# K1921VK028 register map
Vendor: NIIET; Series: K1921VKx; File version: 2.17
CPU: CM4 r0p1, little endian, MPU, FPU, 4 interrupt priority bits
Registers are 32-bit, read-write, reset 0x0 unless marked. A register's access mark holds for its fields unless they carry their own. Offsets are from the block's base; [hi:lo] are bit positions; lines under a group give offsets from that group; {n}, {i} and the like mark numbered series; 'fields as' and 'values as' point back to an identical list.

## RCU — Reset and clock unit registers
Base 0x40081000
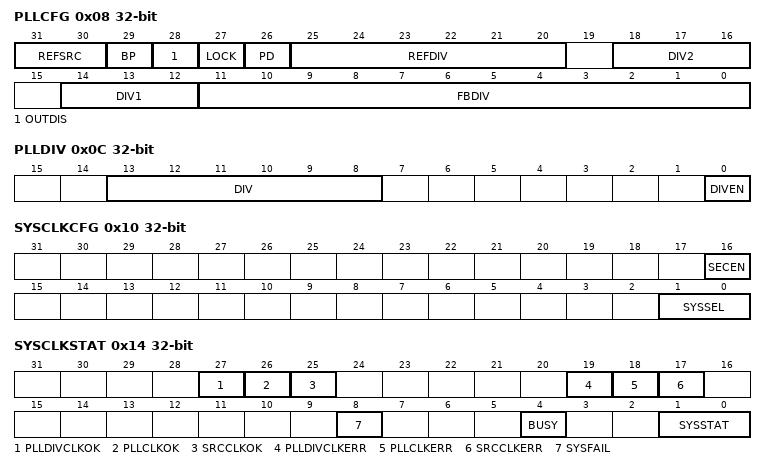
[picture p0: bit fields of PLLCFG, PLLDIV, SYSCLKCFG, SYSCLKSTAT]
0x08 PLLCFG — PLL Configuration Register
  [31:30] REFSRC — Reference clock source
    0=OSECLK (external oscillator); 1=OSICLK (internal oscillator); 2=PLLEXTCLK (external PLL clock source)
  [29] BP — Bypass PLL reference clock
  [28] OUTDIS — Disable PLL output clock
  [27] LOCK ro — Lock status of stable PLL output clock
  [26] PD — PLL PowerDown enable bit
  [25:20] REFDIV — PLL reference clock divider
  [18:16] DIV2 — Output DIV2 coefficient
  [14:12] DIV1 — Output DIV1 coefficient
  [11:0] FBDIV — PLL FBDIV Coefficient
0x0C PLLDIV — PLL Divider Register
  [13:8] DIV — PLL divider coefficent
  [0] DIVEN — PLL Divider enable bit
0x10 SYSCLKCFG — System Clock Configuration Register
  [16] SECEN — Enable clock security system
  [1:0] SYSSEL — System clock source selection
    0=REFCLK (reference clock); 1=SRCCLK (additional clock source); 2=PLLCLK (PLL output clock); 3=PLLDIVCLK (PLL divided clock)
0x14 SYSCLKSTAT ro — System Clock Status Register
  [27] PLLDIVCLKOK — PLL divided clock good
  [26] PLLCLKOK — PLL clock good
  [25] SRCCLKOK — Additional clock source good
  [19] PLLDIVCLKERR — PLL divided clock fail
  [18] PLLCLKERR — PLL clock fail
  [17] SRCCLKERR — Additional clock source fail
  [8] SYSFAIL — Error in current clock was detected
  [4] BUSY — Clock manager is busy, for example, when change clock source
  [1:0] SYSSTAT — Current system clock source
    on read: 0=REFCLK (reference clock); 1=SRCCLK (additional clock source); 2=PLLCLK (PLL output clock); 3=PLLDIVCLK (PLL divided clock)
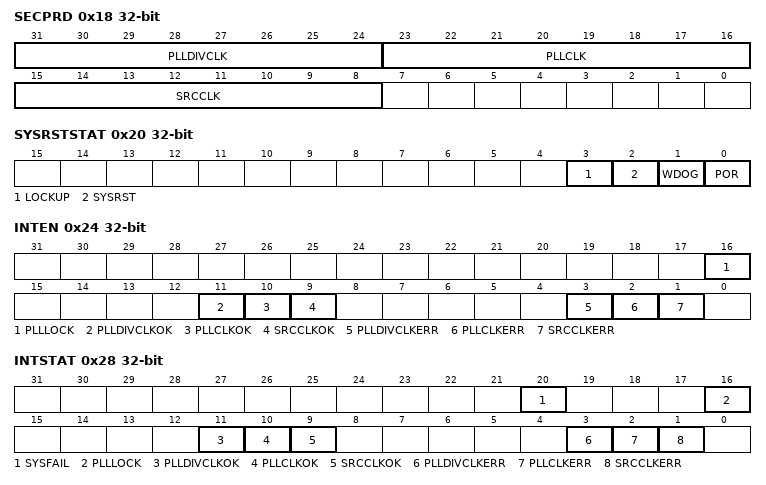
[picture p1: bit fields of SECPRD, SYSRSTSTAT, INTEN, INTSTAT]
0x18 SECPRD — Security Sysytem Clock Period Register 0
  [31:24] PLLDIVCLK — Clock source 3 max counter value for clock fail detection
  [23:16] PLLCLK — Clock source 2 max counter value for clock fail detection
  [15:8] SRCCLK — Additional clock source max counter value for fail detection
0x1C SYSRSTCFG — System Reset Configuration Register
  [0] LOCKUPEN — Enable reset when processor in LOCKUP state
0x20 SYSRSTSTAT — Reset Status Register
  [3] LOCKUP — Lockup Reset Status
  [2] SYSRST — System Reset Status
  [1] WDOG — WatchDog Reset status
  [0] POR — PowerOn Reset status
0x24 INTEN — Interrupt Enable Register
  [16] PLLLOCK — Enable int from pll lock signal
  [11] PLLDIVCLKOK — Enable PLLDIVCLK good interrupt
  [10] PLLCLKOK — Enable PLLCLK good interrupt
  [9] SRCCLKOK — Enable SRCCLK good interrupt
  [3] PLLDIVCLKERR — Enable PLLDIVCLK fail interrupt
  [2] PLLCLKERR — Enable PLLCLK fail interrupt
  [1] SRCCLKERR — Enable SRCCLK fail interrupt
0x28 INTSTAT — Interrupt Status Register
  [20] SYSFAIL — SYSCLK fail status
  [16] PLLLOCK — Status pll lock signal
  [11] PLLDIVCLKOK — Status PLLDIVCLK good
  [10] PLLCLKOK — Status PLLCLK good
  [9] SRCCLKOK — Status SRCCLK good
  [3] PLLDIVCLKERR — Status PLLDIVCLK fail
  [2] PLLCLKERR — Status PLLCLK fail
  [1] SRCCLKERR — Status SRCCLK fail
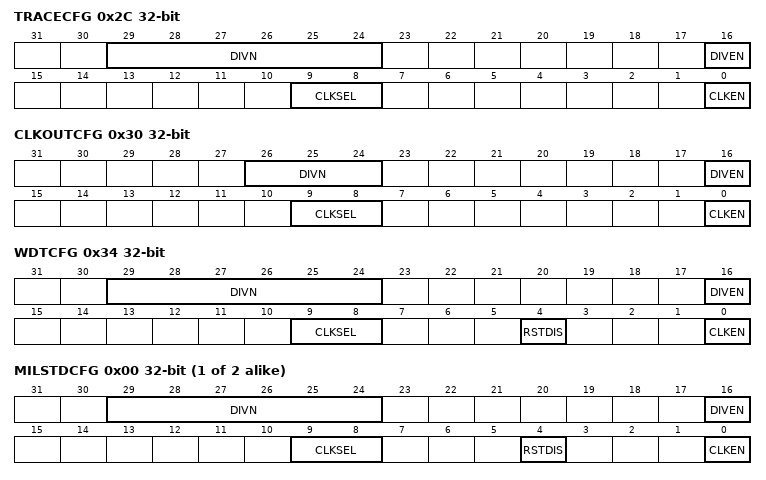
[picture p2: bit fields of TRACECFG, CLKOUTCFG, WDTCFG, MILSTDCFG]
0x2C TRACECFG — Trace Clock Configuration Register
  [29:24] DIVN — Divider coefficient
  [16] DIVEN — Enable divider
  [9:8] CLKSEL — Clock source select
    0=REFCLK (reference clock); 1=SRCCLK (additional clock source); 2=SYSCLK (System clock); 3=TRACEEXTCLK (Trace external clock)
  [0] CLKEN — Clock enable
0x30 CLKOUTCFG — Clockout Configuration Register
  [26:24] DIVN — Divider coefficient
  [16] DIVEN — Enable divider
  [9:8] CLKSEL — Clock source select
    0=REFCLK (reference clock); 1=SRCCLK (additional clock source); 2=SYSCLK (System clock); 3=PLLCLK (PLL output clock)
  [0] CLKEN — Clock enable
0x34 WDTCFG — WatchDog Configuration Register
  [29:24] DIVN — Divider coefficient
  [16] DIVEN — Enable divider
  [9:8] CLKSEL — Clock source select
    values as CLKOUTCFG.CLKSEL
  [4] RSTDIS — Reset disable
  [0] CLKEN — Clock enable
{0x40+4i} MILSTDCFG[{i}] (i=0..1) group
  0x00 MILSTDCFG — MILSTD Codec Clock and Reset Configuration Register
    [29:24] DIVN — Divider coefficient
    [16] DIVEN — Enable divider
    [9:8] CLKSEL — Clock source select
      0=OSECLK (external oscillator); 1=PLLCLK (PLL output clock); 2=PLLDIVCLK (PLL divided clock); 3=PLLEXTCLK (external PLL clock source)
    [4] RSTDIS — Reset disable
    [0] CLKEN — Clock enable
{0x50+4i} SPWRCFG[{i}] (i=0..1) group
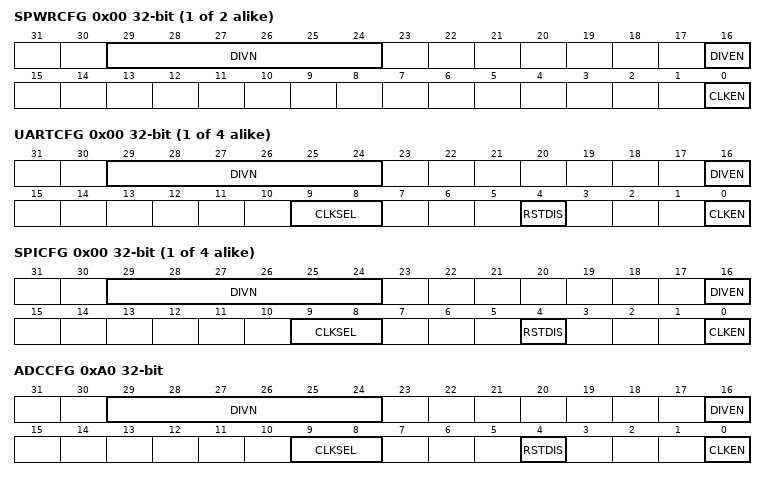
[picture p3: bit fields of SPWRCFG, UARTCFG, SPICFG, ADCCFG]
  0x00 SPWRCFG — SPWR TX Clock Configuration Register
    [29:24] DIVN — Divider coefficient
    [16] DIVEN — Enable divider
    [0] CLKEN — Clock enable
{0x60+4i} UARTCFG[{i}] (i=0..3) group
  0x00 UARTCFG — UART Clock and Reset Configuration Register
    fields as MILSTDCFG[0].MILSTDCFG
{0x80+4i} SPICFG[{i}] (i=0..3) group
  0x00 SPICFG — SPI Clock and Reset Configuration Register
    fields as MILSTDCFG[0].MILSTDCFG
0xA0 ADCCFG — ADC Clock and Reset Configuration Register
  fields as MILSTDCFG[0].MILSTDCFG
0xC0 APBCFG — APB Clock Configuraton Register
  [1:0] DIV — Divider coefficent
    0=None (no divide); 1=divide by 2; 2=divide by 4; 3=divide by 8
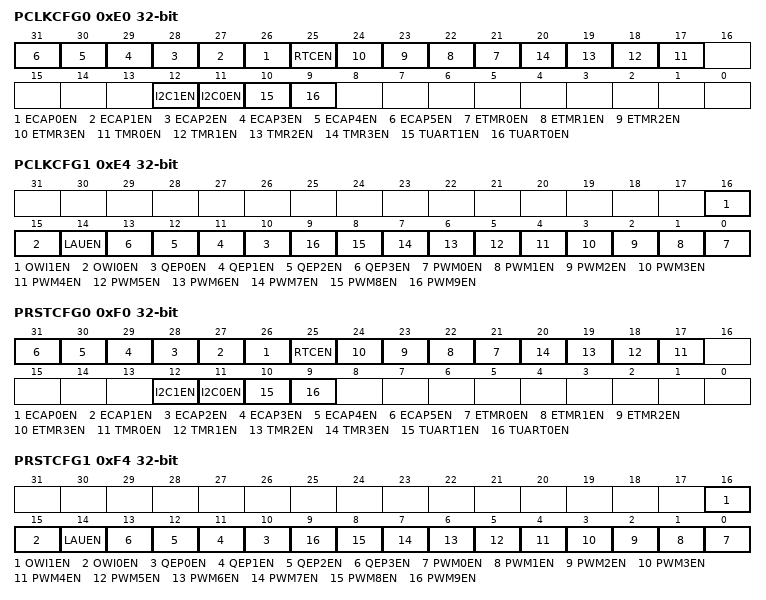
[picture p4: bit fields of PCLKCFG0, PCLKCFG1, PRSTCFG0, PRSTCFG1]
0xE0 PCLKCFG0 — APB Clock Configuration Register 0
  [n+26] ECAP{n}EN (n=0..5) — CAP{n} clock enable
  [25] RTCEN — RTC clock enable
  [n+21] ETMR{n}EN (n=0..3) — ETMR{n} clock enable
  [n+17] TMR{n}EN (n=0..3) — TMR{n} clock enable
  [12] I2C1EN — I2C1 clock enable
  [11] I2C0EN — I2C0 clock enable
  [10] TUART1EN — TUART1 clock enable
  [9] TUART0EN — TUART0 clock enable
0xE4 PCLKCFG1 — APB Clock Configuration Register 1
  [16] OWI1EN — OWI1 clock enable
  [15] OWI0EN — OWI0 clock enable
  [14] LAUEN — LAU clock enable
  [n+10] QEP{n}EN (n=0..3) — QEP{n} clock enable
  [n] PWM{n}EN (n=0..9) — PWM{n} clock enable
0xF0 PRSTCFG0 — APB Reset Configuration Register 0
  [n+26] ECAP{n}EN (n=0..5) — CAP{n} reset disable
  [25] RTCEN — RTC reset disable
  [n+21] ETMR{n}EN (n=0..3) — ETMR{n} reset disable
  [n+17] TMR{n}EN (n=0..3) — TMR{n} reset disable
  [12] I2C1EN — I2C1 reset disable
  [11] I2C0EN — I2C0 reset disable
  [10] TUART1EN — TUART1 reset disable
  [9] TUART0EN — TUART0 reset disable
0xF4 PRSTCFG1 — APB Reset Configuration Register 1
  [16] OWI1EN — OWI1 reset disable
  [15] OWI0EN — OWI0 reset disable
  [14] LAUEN — LAU reset disable
  [n+10] QEP{n}EN (n=0..3) — QEP{n} reset disable
  [n] PWM{n}EN (n=0..9) — PWM{n} reset disable
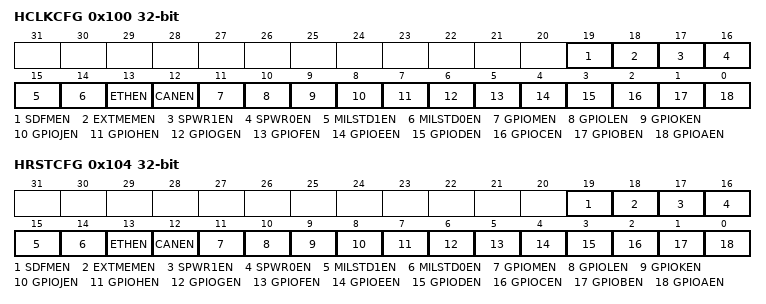
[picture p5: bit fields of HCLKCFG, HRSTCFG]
0x100 HCLKCFG — AHB Clock Configuration Register
  [19] SDFMEN — Enable clock for SDFM
  [18] EXTMEMEN — Enable clock for extmem interface
  [17] SPWR1EN — Enable clock for spacewire 1 interface
  [16] SPWR0EN — Enable clock for spacewire 0 interface
  [15] MILSTD1EN — Enable clock for milstd 1 interface
  [14] MILSTD0EN — Enable clock for milstd 0 interface
  [13] ETHEN — Enable clock for ethernet
  [12] CANEN — Enable clock for CAN interface
  [11] GPIOMEN — Enable clock for GPIOM port
  [10] GPIOLEN — Enable clock for GPIOL port
  [9] GPIOKEN — Enable clock for GPIOK port
  [8] GPIOJEN — Enable clock for GPIOJ port
  [7] GPIOHEN — Enable clock for GPIOH port
  [6] GPIOGEN — Enable clock for GPIOG port
  [5] GPIOFEN — Enable clock for GPIOF port
  [4] GPIOEEN — Enable clock for GPIOE port
  [3] GPIODEN — Enable clock for GPIOD port
  [2] GPIOCEN — Enable clock for GPIOC port
  [1] GPIOBEN — Enable clock for GPIOB port
  [0] GPIOAEN — Enable clock for GPIOA port
0x104 HRSTCFG — AHB Reset Configuration Register
  [19] SDFMEN — Disable reset from SDFM
  [18] EXTMEMEN — Disable reset from extmem interface
  [17] SPWR1EN — Disable reset from spacewire 1 interface
  [16] SPWR0EN — Disable reset from spacewire 0 interface
  [15] MILSTD1EN — Disable reset from milstd 1 nterface
  [14] MILSTD0EN — Disable reset from milstd 0 interface
  [13] ETHEN — Disable reset from Ethernet
  [12] CANEN — Disable reset from CAN interface
  [11] GPIOMEN — Disable reset from GPIOM port
  [10] GPIOLEN — Disable reset from GPIOL port
  [9] GPIOKEN — Disable reset from GPIOK port
  [8] GPIOJEN — Disable reset from GPIOJ port
  [7] GPIOHEN — Disable reset from GPIOH port
  [6] GPIOGEN — Disable reset from GPIOG port
  [5] GPIOFEN — Disable reset from GPIOF port
  [4] GPIOEEN — Disable reset from GPIOE port
  [3] GPIODEN — Disable reset from GPIOD port
  [2] GPIOCEN — Disable reset from GPIOC port
  [1] GPIOBEN — Disable reset from GPIOB port
  [0] GPIOAEN — Disable reset from GPIOA port
